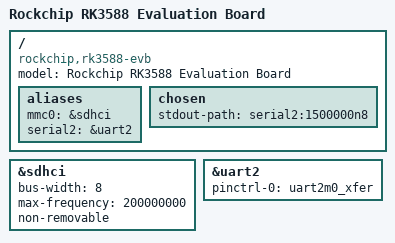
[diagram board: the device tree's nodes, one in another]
// SPDX-License-Identifier: (GPL-2.0+ OR MIT)
/*
 * Copyright (c) 2021 Rockchip Electronics Co., Ltd
 *
 */

/dts-v1/;
#include "rk3588.dtsi"

/ {
	model = "Rockchip RK3588 Evaluation Board";
	compatible = "rockchip,rk3588-evb", "rockchip,rk3588";

	aliases {
		mmc0 = &sdhci;
		serial2 = &uart2;
	};

	chosen {
		stdout-path = "serial2:1500000n8";
	};
};

&sdhci {
	bus-width = <8>;
	max-frequency = <200000000>;
	non-removable;
	status = "okay";
};

&uart2 {
	pinctrl-0 = <&uart2m0_xfer>;
	status = "okay";
};
